# S1C31D50 register map
Vendor: Epson; Series: S1C31D50; File version: 1.00
CPU: CM0PLUS r0p1, little endian, MPU, no FPU, VTOR, 2 interrupt priority bits
Registers are 16-bit, read-write, reset 0x0 unless marked. A register's access mark holds for its fields unless they carry their own. Offsets are from the block's base; [hi:lo] are bit positions; {n}, {i} and the like mark numbered series; 'fields as' and 'values as' point back to an identical list.

## SYS — System register
Base 0x00200000
0x00 PROT — Register Write Protect Register
  [15:0] PROT — Register write protect

## T16_0 — 16 Timer / Counter, counting up or down from different sources
Base 0x00200160
Same registers: T16_1 0x002003A0, T16_3 0x00200480, T16_4 0x002004A0, T16_5 0x002004C0, T16_6 0x00200660, T16_2 0x00200680, T16_7 0x00200780
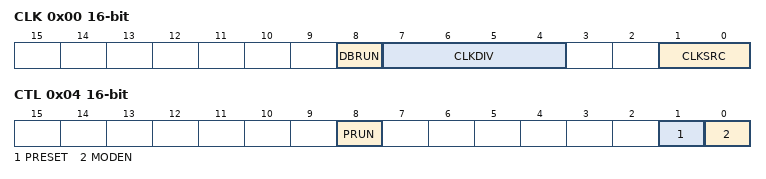
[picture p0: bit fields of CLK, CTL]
0x00 CLK — Clock Control Register
  [8] DBRUN — Enable clock on debug mode
    0=STOP (Timer is stopped and does not operate); 1=RUN (Timer is started and operates)
  [7:4] CLKDIV — Clock division ratio
  [1:0] CLKSRC — Clock source select
    3=EXOSC (External OSC); 2=OSC3; 1=OSC1; 0=IOSC
0x02 MOD — Mode Register
  [0] TRMD — Repeat mode select
    1=ONE_SHOT; 0=REPEAT
0x04 CTL — Channel 0 Control Register
  [8] PRUN — Run Stop bit
    values as CLK.DBRUN
  [1] PRESET — Timer reset
    on write: 0=NO_ACTION (No action when written, no reset when read); 1=RESET (Reset timer when written, reset pending when read) | on read: 0=NO_RESET (No action when written, no reset when read); 1=RESET_PENDING (Reset timer when written, reset pending when read)
  [0] MODEN — Timer (T16) enable
    0=DISABLE (Disable timer); 1=ENABLE (Enable timer)
0x06 TR reset 0xFFFF — Reload Data Register
  [15:0] TR — Timer reload value
0x08 TC ro reset 0xFFFF — Counter Data Register
  [15:0] TC — Timer count value
0x0A INTF — Interrupt Flag Register
  [0] UFIF write-1-clears — Underflow interrupt flag
    0=NOT_OCCURED (No cause of interrupt occurred); 1=OCCURED (Cause of interrupt occurred)
0x0C INTE — Interrupt Enable Register
  [0] UFIE — Underflow interrupt enable
    0=DISABLE; 1=ENABLE

## UPMUX — Universal port multiplexer control
Base 0x00200300
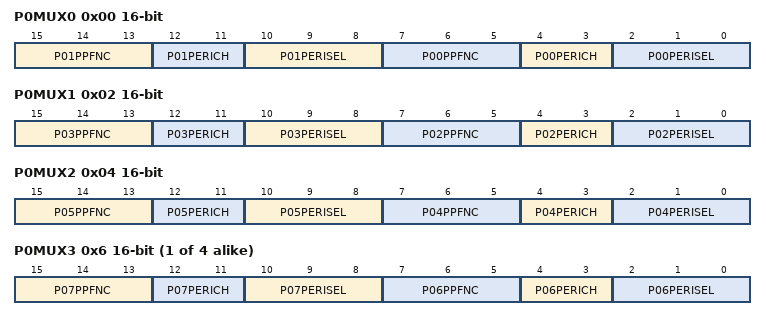
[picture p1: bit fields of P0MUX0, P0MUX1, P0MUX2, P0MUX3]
0x00 P0MUX0 — P00_01 Universal Port Multiplexer Setting Register
  [15:13] P01PPFNC — Assign pin function
  [12:11] P01PERICH — Assign Peripheral channel
  [10:8] P01PERISEL — Assign peripheral
  [7:5] P00PPFNC — Assign pin function
  [4:3] P00PERICH — Assign Peripheral channel
  [2:0] P00PERISEL — Assign peripheral
0x02 P0MUX1 — P02_03 Universal Port Multiplexer Setting Register
  [15:13] P03PPFNC — Assign pin function
  [12:11] P03PERICH — Assign peripheral channel
  [10:8] P03PERISEL — Assign peripheral
  [7:5] P02PPFNC — Assign pin function
  [4:3] P02PERICH — Assign Peripheral channel
  [2:0] P02PERISEL — Assign peripheral
0x04 P0MUX2 — P04_05 Universal Port Multiplexer Setting Register
  [15:13] P05PPFNC — Assign pin function
  [12:11] P05PERICH — Assign Peripheral channel
  [10:8] P05PERISEL — Assign peripheral
  [7:5] P04PPFNC — Assign pin function
  [4:3] P04PERICH — Assign Peripheral channel
  [2:0] P04PERISEL — Assign peripheral
{0x6+8i} P{i}MUX3 (i=0..3) — P{10i+6:02}_{10i+7:02} Universal Port Multiplexer Setting Register
  [15:13] P{10i+7:02}PPFNC — Assign pin function
  [12:11] P{10i+7:02}PERICH — Assign Peripheral channel
  [10:8] P{10i+7:02}PERISEL — Assign peripheral
  [7:5] P{10i+6:02}PPFNC — Assign pin function
  [4:3] P{10i+6:02}PERICH — Assign Peripheral channel
  [2:0] P{10i+6:02}PERISEL — Assign peripheral
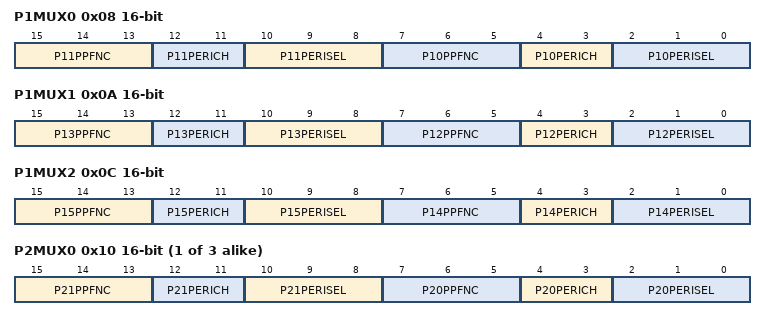
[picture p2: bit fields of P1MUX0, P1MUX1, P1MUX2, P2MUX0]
0x08 P1MUX0 — P10_11 Universal Port Multiplexer Setting Register
  [15:13] P11PPFNC — Assign pin function
  [12:11] P11PERICH — Assign Peripheral channel
  [10:8] P11PERISEL — Assign peripheral
  [7:5] P10PPFNC — Assign pin function
  [4:3] P10PERICH — Assign Peripheral channel
  [2:0] P10PERISEL — Assign peripheral
0x0A P1MUX1 — P12_13 Universal Port Multiplexer Setting Register
  [15:13] P13PPFNC — Assign pin function
  [12:11] P13PERICH — Assign Peripheral channel
  [10:8] P13PERISEL — Assign peripheral
  [7:5] P12PPFNC — Assign pin function
  [4:3] P12PERICH — Assign Peripheral channel
  [2:0] P12PERISEL — Assign peripheral
0x0C P1MUX2 — P14_15 Universal Port Multiplexer Setting Register
  [15:13] P15PPFNC — Assign pin function
  [12:11] P15PERICH — Assign Peripheral channel
  [10:8] P15PERISEL — Assign peripheral
  [7:5] P14PPFNC — Assign pin function
  [4:3] P14PERICH — Assign Peripheral channel
  [2:0] P14PERISEL — Assign peripheral
{0x10+2i} P2MUX{i} (i=0..2) — P{2i+20}_{2i+21} Universal Port Multiplexer Setting Register
  [15:13] P{2i+21}PPFNC — Assign pin function
  [12:11] P{2i+21}PERICH — Assign peripheral channel
  [10:8] P{2i+21}PERISEL — Assign peripheral
  [7:5] P{2i+20}PPFNC — Assign pin function
  [4:3] P{2i+20}PERICH — Assign peripheral channel
  [2:0] P{2i+20}PERISEL — Assign peripheral
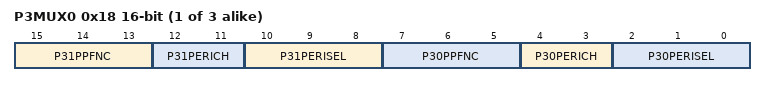
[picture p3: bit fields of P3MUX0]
{0x18+2i} P3MUX{i} (i=0..2) — P{2i+30}_{2i+31} Universal Port Multiplexer Setting Register
  [15:13] P{2i+31}PPFNC — Assign pin function
  [12:11] P{2i+31}PERICH — Assign peripheral channel
  [10:8] P{2i+31}PERISEL — Assign peripheral
  [7:5] P{2i+30}PPFNC — Assign pin function
  [4:3] P{2i+30}PERICH — Assign peripheral channel
  [2:0] P{2i+30}PERISEL — Assign peripheral
